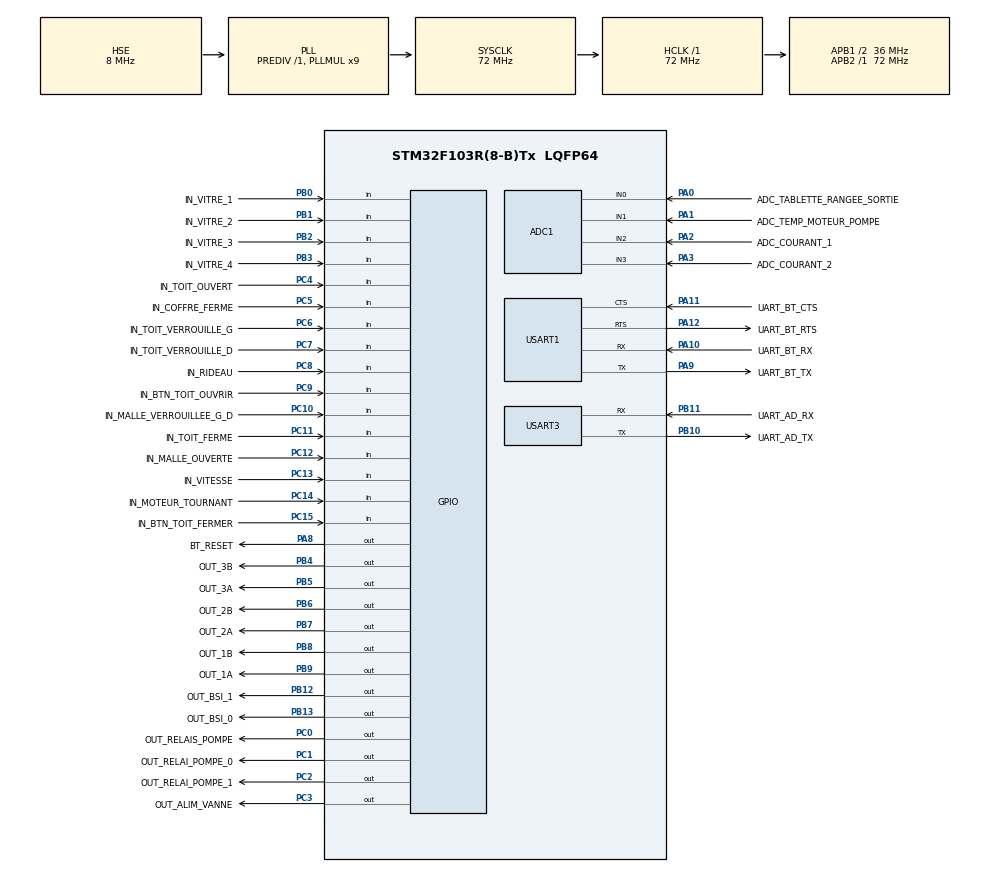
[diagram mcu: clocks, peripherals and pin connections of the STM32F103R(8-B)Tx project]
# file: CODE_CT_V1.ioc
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ADC1.Channel-3\#ChannelRegularConversion=ADC_CHANNEL_0
ADC1.Channel-4\#ChannelRegularConversion=ADC_CHANNEL_1
ADC1.Channel-5\#ChannelRegularConversion=ADC_CHANNEL_2
ADC1.Channel-6\#ChannelRegularConversion=ADC_CHANNEL_3
ADC1.Channel-7\#ChannelRegularConversion=ADC_CHANNEL_TEMPSENSOR
ADC1.ContinuousConvMode=ENABLE
ADC1.NbrOfConversion=5
ADC1.NbrOfConversionFlag=1
ADC1.Rank-3\#ChannelRegularConversion=1
ADC1.Rank-4\#ChannelRegularConversion=2
ADC1.Rank-5\#ChannelRegularConversion=3
ADC1.Rank-6\#ChannelRegularConversion=4
ADC1.Rank-7\#ChannelRegularConversion=5
ADC1.SamplingTime-3\#ChannelRegularConversion=ADC_SAMPLETIME_239CYCLES_5
ADC1.SamplingTime-4\#ChannelRegularConversion=ADC_SAMPLETIME_239CYCLES_5
ADC1.SamplingTime-5\#ChannelRegularConversion=ADC_SAMPLETIME_239CYCLES_5
ADC1.SamplingTime-6\#ChannelRegularConversion=ADC_SAMPLETIME_239CYCLES_5
ADC1.SamplingTime-7\#ChannelRegularConversion=ADC_SAMPLETIME_239CYCLES_5
ADC1.master=1
Dma.ADC1.0.Direction=DMA_PERIPH_TO_MEMORY
Dma.ADC1.0.Instance=DMA1_Channel1
Dma.ADC1.0.MemDataAlignment=DMA_MDATAALIGN_HALFWORD
Dma.ADC1.0.MemInc=DMA_MINC_ENABLE
Dma.ADC1.0.Mode=DMA_CIRCULAR
Dma.ADC1.0.PeriphDataAlignment=DMA_PDATAALIGN_HALFWORD
Dma.ADC1.0.PeriphInc=DMA_PINC_DISABLE
Dma.ADC1.0.Priority=DMA_PRIORITY_LOW
Dma.Request0=ADC1
FREERTOS.Tasks01=TaskToit,40,256,StartTaskToit,Default,NULL,Dynamic,NULL,NULL;TaskBle,24,512,StartTaskBle,Default,NULL,Dynamic,NULL,NULL;TaskDiag,8,128,StartTaskDiag,Default,NULL,Dynamic,NULL,NULL
FREERTOS.configCHECK_FOR_STACK_OVERFLOW=2
FREERTOS.configTOTAL_HEAP_SIZE=10240
Mcu.Family=STM32F1
Mcu.Name=STM32F103R(8-B)Tx
Mcu.Package=LQFP64
NVIC.DMA1_Channel1_IRQn=true\:5\:0\:false\:false\:true\:true\:false\:true\:true
NVIC.PriorityGroup=NVIC_PRIORITYGROUP_4
NVIC.TIM4_IRQn=true\:15\:0\:false\:false\:true\:false\:false\:true\:true
NVIC.TimeBase=TIM4_IRQn
NVIC.TimeBaseIP=TIM4
NVIC.USART1_IRQn=true\:5\:0\:false\:false\:true\:true\:true\:true\:true
PA0-WKUP.GPIO_Label=ADC_TABLETTE_RANGEE_SORTIE
PA0-WKUP.Signal=ADCx_IN0
PA1.GPIO_Label=ADC_TEMP_MOTEUR_POMPE
PA1.Signal=ADCx_IN1
PA10.GPIO_Label=UART_BT_RX
PA10.Mode=Asynchronous
PA10.Signal=USART1_RX
PA11.GPIO_Label=UART_BT_CTS
PA11.Mode=CTS_RTS
PA11.Signal=USART1_CTS
PA12.GPIO_Label=UART_BT_RTS
PA12.Mode=CTS_RTS
PA12.Signal=USART1_RTS
PA13.Mode=Serial_Wire
PA13.Signal=SYS_JTMS-SWDIO
PA14.Mode=Serial_Wire
PA14.Signal=SYS_JTCK-SWCLK
PA2.GPIO_Label=ADC_COURANT_1
PA2.Signal=ADCx_IN2
PA3.GPIO_Label=ADC_COURANT_2
PA3.Signal=ADCx_IN3
PA8.GPIO_Label=BT_RESET
PA8.Signal=GPIO_Output
PA9.GPIO_Label=UART_BT_TX
PA9.Mode=Asynchronous
PA9.Signal=USART1_TX
PB0.GPIO_Label=IN_VITRE_1
PB0.Signal=GPIO_Input
PB1.GPIO_Label=IN_VITRE_2
PB1.Signal=GPIO_Input
PB10.GPIO_Label=UART_AD_TX
PB10.Mode=Asynchronous
PB10.Signal=USART3_TX
PB11.GPIO_Label=UART_AD_RX
PB11.Mode=Asynchronous
PB11.Signal=USART3_RX
PB12.GPIO_Label=OUT_BSI_1
PB12.Signal=GPIO_Output
PB13.GPIO_Label=OUT_BSI_0
PB13.Signal=GPIO_Output
PB2.GPIO_Label=IN_VITRE_3
PB2.Signal=GPIO_Input
PB3.GPIO_Label=IN_VITRE_4
PB3.Signal=GPIO_Input
PB4.GPIO_Label=OUT_3B
PB4.Signal=GPIO_Output
PB5.GPIO_Label=OUT_3A
PB5.Signal=GPIO_Output
PB6.GPIO_Label=OUT_2B
PB6.Signal=GPIO_Output
PB7.GPIO_Label=OUT_2A
PB7.Signal=GPIO_Output
PB8.GPIO_Label=OUT_1B
PB8.Signal=GPIO_Output
PB9.GPIO_Label=OUT_1A
PB9.Signal=GPIO_Output
PC0.GPIO_Label=OUT_RELAIS_POMPE
PC0.Signal=GPIO_Output
PC1.GPIO_Label=OUT_RELAI_POMPE_0
PC1.Signal=GPIO_Output
PC10.GPIO_Label=IN_MALLE_VERROUILLEE_G_D
PC10.Signal=GPIO_Input
PC11.GPIO_Label=IN_TOIT_FERME
PC11.Signal=GPIO_Input
PC12.GPIO_Label=IN_MALLE_OUVERTE
PC12.Signal=GPIO_Input
PC13-TAMPER-RTC.GPIO_Label=IN_VITESSE
PC13-TAMPER-RTC.Signal=GPIO_Input
PC14-OSC32_IN.GPIO_Label=IN_MOTEUR_TOURNANT
PC14-OSC32_IN.Signal=GPIO_Input
PC15-OSC32_OUT.GPIO_Label=IN_BTN_TOIT_FERMER
PC15-OSC32_OUT.Signal=GPIO_Input
PC2.GPIO_Label=OUT_RELAI_POMPE_1
PC2.Signal=GPIO_Output
PC3.GPIO_Label=OUT_ALIM_VANNE
PC3.Signal=GPIO_Output
PC4.GPIO_Label=IN_TOIT_OUVERT
PC4.Signal=GPIO_Input
PC5.GPIO_Label=IN_COFFRE_FERME
PC5.Signal=GPIO_Input
PC6.GPIO_Label=IN_TOIT_VERROUILLE_G
PC6.Signal=GPIO_Input
PC7.GPIO_Label=IN_TOIT_VERROUILLE_D
PC7.Signal=GPIO_Input
PC8.GPIO_Label=IN_RIDEAU
PC8.Signal=GPIO_Input
PC9.GPIO_Label=IN_BTN_TOIT_OUVRIR
PC9.Signal=GPIO_Input
PD0-OSC_IN.Mode=HSE-External-Oscillator
PD0-OSC_IN.Signal=RCC_OSC_IN
PD1-OSC_OUT.Mode=HSE-External-Oscillator
PD1-OSC_OUT.Signal=RCC_OSC_OUT
ProjectManager.HeapSize=0x200
ProjectManager.StackSize=0x400
ProjectManager.TargetToolchain=CMake
RCC.ADCPresc=RCC_ADCPCLK2_DIV6
RCC.AHBFreq_Value=72000000
RCC.APB1CLKDivider=RCC_HCLK_DIV2
RCC.APB1Freq_Value=36000000
RCC.APB1TimFreq_Value=72000000
RCC.APB2Freq_Value=72000000
RCC.APB2TimFreq_Value=72000000
RCC.HCLKFreq_Value=72000000
RCC.PLLMUL=RCC_PLL_MUL9
RCC.PLLSourceVirtual=RCC_PLLSOURCE_HSE
RCC.SYSCLKFreq_VALUE=72000000
RCC.SYSCLKSource=RCC_SYSCLKSOURCE_PLLCLK
RCC.USBFreq_Value=72000000
SH.ADCx_IN0.0=ADC1_IN0,IN0
SH.ADCx_IN1.0=ADC1_IN1,IN1
SH.ADCx_IN2.0=ADC1_IN2,IN2
SH.ADCx_IN3.0=ADC1_IN3,IN3
USART1.VirtualMode=VM_ASYNC
USART3.VirtualMode=VM_ASYNC
VP_ADC1_TempSens_Input.Mode=IN-TempSens
VP_FREERTOS_VS_CMSIS_V2.Mode=CMSIS_V2
VP_SYS_VS_tim4.Mode=TIM4
board=custom

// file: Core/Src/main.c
/* USER CODE BEGIN Header */
/**
  ******************************************************************************
  * @file           : main.c
  * @brief          : Main program body
  ******************************************************************************
  * @attention
  *
  * Copyright (c) 2026 STMicroelectronics.
  * All rights reserved.
  *
  * This software is licensed under terms that can be found in the LICENSE file
  * in the root directory of this software component.
  * If no LICENSE file comes with this software, it is provided AS-IS.
  *
  ******************************************************************************
  */
/* USER CODE END Header */
#include "main.h"
#include "cmsis_os.h"

/* USER CODE BEGIN Includes */
#include "vitres.h"
/* USER CODE END Includes */

ADC_HandleTypeDef hadc1;
DMA_HandleTypeDef hdma_adc1;

UART_HandleTypeDef huart1;
UART_HandleTypeDef huart3;

/* Definitions for TaskToit */
osThreadId_t TaskToitHandle;
const osThreadAttr_t TaskToit_attributes = {
  .name = "TaskToit",
  .stack_size = 256 * 4,
  .priority = (osPriority_t) osPriorityHigh,
};
/* Definitions for TaskBle */
osThreadId_t TaskBleHandle;
const osThreadAttr_t TaskBle_attributes = {
  .name = "TaskBle",
  .stack_size = 512 * 4,
  .priority = (osPriority_t) osPriorityNormal,
};
/* Definitions for TaskDiag */
osThreadId_t TaskDiagHandle;
const osThreadAttr_t TaskDiag_attributes = {
  .name = "TaskDiag",
  .stack_size = 128 * 4,
  .priority = (osPriority_t) osPriorityLow,
};

void SystemClock_Config(void);
static void MX_GPIO_Init(void);
static void MX_DMA_Init(void);
static void MX_USART1_UART_Init(void);
static void MX_USART3_UART_Init(void);
static void MX_ADC1_Init(void);
void StartTaskToit(void *argument);
void StartTaskBle(void *argument);
void StartTaskDiag(void *argument);

int main(void)
{

  /* MCU Configuration--------------------------------------------------------*/

  /* Reset of all peripherals, Initializes the Flash interface and the Systick. */
  HAL_Init();

  /* Configure the system clock */
  SystemClock_Config();

  /* Initialize all configured peripherals */
  MX_GPIO_Init();
  MX_DMA_Init();
  MX_USART1_UART_Init();
  MX_USART3_UART_Init();
  MX_ADC1_Init();

  /* Init scheduler */
  osKernelInitialize();

  /* Create the thread(s) */
  /* creation of TaskToit */
  TaskToitHandle = osThreadNew(StartTaskToit, NULL, &TaskToit_attributes);

  /* creation of TaskBle */
  TaskBleHandle = osThreadNew(StartTaskBle, NULL, &TaskBle_attributes);

  /* creation of TaskDiag */
  TaskDiagHandle = osThreadNew(StartTaskDiag, NULL, &TaskDiag_attributes);

  /* Start scheduler */
  osKernelStart();

  /* We should never get here as control is now taken by the scheduler */

  /* Infinite loop */
  while (1)
  {

  }
}

void SystemClock_Config(void)
{
  RCC_OscInitTypeDef RCC_OscInitStruct = {0};
  RCC_ClkInitTypeDef RCC_ClkInitStruct = {0};
  RCC_PeriphCLKInitTypeDef PeriphClkInit = {0};

  /** Initializes the RCC Oscillators according to the specified parameters
  * in the RCC_OscInitTypeDef structure.
  */
  RCC_OscInitStruct.OscillatorType = RCC_OSCILLATORTYPE_HSE;
  RCC_OscInitStruct.HSEState = RCC_HSE_ON;
  RCC_OscInitStruct.HSEPredivValue = RCC_HSE_PREDIV_DIV1;
  RCC_OscInitStruct.HSIState = RCC_HSI_ON;
  RCC_OscInitStruct.PLL.PLLState = RCC_PLL_ON;
  RCC_OscInitStruct.PLL.PLLSource = RCC_PLLSOURCE_HSE;
  RCC_OscInitStruct.PLL.PLLMUL = RCC_PLL_MUL9;
  if (HAL_RCC_OscConfig(&RCC_OscInitStruct) != HAL_OK)
  {
    Error_Handler();
  }

  /** Initializes the CPU, AHB and APB buses clocks
  */
  RCC_ClkInitStruct.ClockType = RCC_CLOCKTYPE_HCLK|RCC_CLOCKTYPE_SYSCLK
                              |RCC_CLOCKTYPE_PCLK1|RCC_CLOCKTYPE_PCLK2;
  RCC_ClkInitStruct.SYSCLKSource = RCC_SYSCLKSOURCE_PLLCLK;
  RCC_ClkInitStruct.AHBCLKDivider = RCC_SYSCLK_DIV1;
  RCC_ClkInitStruct.APB1CLKDivider = RCC_HCLK_DIV2;
  RCC_ClkInitStruct.APB2CLKDivider = RCC_HCLK_DIV1;

  if (HAL_RCC_ClockConfig(&RCC_ClkInitStruct, FLASH_LATENCY_2) != HAL_OK)
  {
    Error_Handler();
  }
  PeriphClkInit.PeriphClockSelection = RCC_PERIPHCLK_ADC;
  PeriphClkInit.AdcClockSelection = RCC_ADCPCLK2_DIV6;
  if (HAL_RCCEx_PeriphCLKConfig(&PeriphClkInit) != HAL_OK)
  {
    Error_Handler();
  }
}

static void MX_ADC1_Init(void)
{

  ADC_ChannelConfTypeDef sConfig = {0};

  /** Common config
  */
  hadc1.Instance = ADC1;
  hadc1.Init.ScanConvMode = ADC_SCAN_ENABLE;
  hadc1.Init.ContinuousConvMode = ENABLE;
  hadc1.Init.DiscontinuousConvMode = DISABLE;
  hadc1.Init.ExternalTrigConv = ADC_SOFTWARE_START;
  hadc1.Init.DataAlign = ADC_DATAALIGN_RIGHT;
  hadc1.Init.NbrOfConversion = 5;
  if (HAL_ADC_Init(&hadc1) != HAL_OK)
  {
    Error_Handler();
  }

  /** Configure Regular Channel
  */
  sConfig.Channel = ADC_CHANNEL_0;
  sConfig.Rank = ADC_REGULAR_RANK_1;
  sConfig.SamplingTime = ADC_SAMPLETIME_239CYCLES_5;
  if (HAL_ADC_ConfigChannel(&hadc1, &sConfig) != HAL_OK)
  {
    Error_Handler();
  }

  /** Configure Regular Channel
  */
  sConfig.Channel = ADC_CHANNEL_1;
  sConfig.Rank = ADC_REGULAR_RANK_2;
  if (HAL_ADC_ConfigChannel(&hadc1, &sConfig) != HAL_OK)
  {
    Error_Handler();
  }

  /** Configure Regular Channel
  */
  sConfig.Channel = ADC_CHANNEL_2;
  sConfig.Rank = ADC_REGULAR_RANK_3;
  if (HAL_ADC_ConfigChannel(&hadc1, &sConfig) != HAL_OK)
  {
    Error_Handler();
  }

  /** Configure Regular Channel
  */
  sConfig.Channel = ADC_CHANNEL_3;
  sConfig.Rank = ADC_REGULAR_RANK_4;
  if (HAL_ADC_ConfigChannel(&hadc1, &sConfig) != HAL_OK)
  {
    Error_Handler();
  }

  /** Configure Regular Channel
  */
  sConfig.Channel = ADC_CHANNEL_TEMPSENSOR;
  sConfig.Rank = ADC_REGULAR_RANK_5;
  if (HAL_ADC_ConfigChannel(&hadc1, &sConfig) != HAL_OK)
  {
    Error_Handler();
  }

}

static void MX_USART1_UART_Init(void)
{

  huart1.Instance = USART1;
  huart1.Init.BaudRate = 115200;
  huart1.Init.WordLength = UART_WORDLENGTH_8B;
  huart1.Init.StopBits = UART_STOPBITS_1;
  huart1.Init.Parity = UART_PARITY_NONE;
  huart1.Init.Mode = UART_MODE_TX_RX;
  huart1.Init.HwFlowCtl = UART_HWCONTROL_RTS_CTS;
  huart1.Init.OverSampling = UART_OVERSAMPLING_16;
  if (HAL_UART_Init(&huart1) != HAL_OK)
  {
    Error_Handler();
  }

}

static void MX_USART3_UART_Init(void)
{

  huart3.Instance = USART3;
  huart3.Init.BaudRate = 115200;
  huart3.Init.WordLength = UART_WORDLENGTH_8B;
  huart3.Init.StopBits = UART_STOPBITS_1;
  huart3.Init.Parity = UART_PARITY_NONE;
  huart3.Init.Mode = UART_MODE_TX_RX;
  huart3.Init.HwFlowCtl = UART_HWCONTROL_NONE;
  huart3.Init.OverSampling = UART_OVERSAMPLING_16;
  if (HAL_UART_Init(&huart3) != HAL_OK)
  {
    Error_Handler();
  }

}

static void MX_DMA_Init(void)
{

  /* DMA controller clock enable */
  __HAL_RCC_DMA1_CLK_ENABLE();

  /* DMA interrupt init */
  /* DMA1_Channel1_IRQn interrupt configuration */
  HAL_NVIC_SetPriority(DMA1_Channel1_IRQn, 5, 0);
  HAL_NVIC_EnableIRQ(DMA1_Channel1_IRQn);

}

static void MX_GPIO_Init(void)
{
  GPIO_InitTypeDef GPIO_InitStruct = {0};

  /* GPIO Ports Clock Enable */
  __HAL_RCC_GPIOC_CLK_ENABLE();
  __HAL_RCC_GPIOD_CLK_ENABLE();
  __HAL_RCC_GPIOA_CLK_ENABLE();
  __HAL_RCC_GPIOB_CLK_ENABLE();

  /*Configure GPIO pin Output Level */
  HAL_GPIO_WritePin(GPIOC, OUT_RELAIS_POMPE_Pin|OUT_RELAI_POMPE_0_Pin|OUT_RELAI_POMPE_1_Pin|OUT_ALIM_VANNE_Pin, GPIO_PIN_RESET);

  /*Configure GPIO pin Output Level */
  HAL_GPIO_WritePin(GPIOB, OUT_BSI_1_Pin|OUT_BSI_0_Pin|OUT_3B_Pin|OUT_3A_Pin
                          |OUT_2B_Pin|OUT_2A_Pin|OUT_1B_Pin|OUT_1A_Pin, GPIO_PIN_RESET);

  /*Configure GPIO pin Output Level */
  HAL_GPIO_WritePin(BT_RESET_GPIO_Port, BT_RESET_Pin, GPIO_PIN_RESET);

  /*Configure GPIO pins : IN_VITESSE_Pin IN_MOTEUR_TOURNANT_Pin IN_BTN_TOIT_FERMER_Pin IN_TOIT_OUVERT_Pin
                           IN_COFFRE_FERME_Pin IN_TOIT_VERROUILLE_G_Pin IN_TOIT_VERROUILLE_D_Pin IN_RIDEAU_Pin
                           IN_BTN_TOIT_OUVRIR_Pin IN_MALLE_VERROUILLEE_G_D_Pin IN_TOIT_FERME_Pin IN_MALLE_OUVERTE_Pin */
  GPIO_InitStruct.Pin = IN_VITESSE_Pin|IN_MOTEUR_TOURNANT_Pin|IN_BTN_TOIT_FERMER_Pin|IN_TOIT_OUVERT_Pin
                          |IN_COFFRE_FERME_Pin|IN_TOIT_VERROUILLE_G_Pin|IN_TOIT_VERROUILLE_D_Pin|IN_RIDEAU_Pin
                          |IN_BTN_TOIT_OUVRIR_Pin|IN_MALLE_VERROUILLEE_G_D_Pin|IN_TOIT_FERME_Pin|IN_MALLE_OUVERTE_Pin;
  GPIO_InitStruct.Mode = GPIO_MODE_INPUT;
  GPIO_InitStruct.Pull = GPIO_NOPULL;
  HAL_GPIO_Init(GPIOC, &GPIO_InitStruct);

  /*Configure GPIO pins : OUT_RELAIS_POMPE_Pin OUT_RELAI_POMPE_0_Pin OUT_RELAI_POMPE_1_Pin OUT_ALIM_VANNE_Pin */
  GPIO_InitStruct.Pin = OUT_RELAIS_POMPE_Pin|OUT_RELAI_POMPE_0_Pin|OUT_RELAI_POMPE_1_Pin|OUT_ALIM_VANNE_Pin;
  GPIO_InitStruct.Mode = GPIO_MODE_OUTPUT_PP;
  GPIO_InitStruct.Pull = GPIO_NOPULL;
  GPIO_InitStruct.Speed = GPIO_SPEED_FREQ_LOW;
  HAL_GPIO_Init(GPIOC, &GPIO_InitStruct);

  /*Configure GPIO pins : IN_VITRE_1_Pin IN_VITRE_2_Pin IN_VITRE_3_Pin IN_VITRE_4_Pin */
  GPIO_InitStruct.Pin = IN_VITRE_1_Pin|IN_VITRE_2_Pin|IN_VITRE_3_Pin|IN_VITRE_4_Pin;
  GPIO_InitStruct.Mode = GPIO_MODE_INPUT;
  GPIO_InitStruct.Pull = GPIO_NOPULL;
  HAL_GPIO_Init(GPIOB, &GPIO_InitStruct);

  /*Configure GPIO pins : OUT_BSI_1_Pin OUT_BSI_0_Pin OUT_3B_Pin OUT_3A_Pin
                           OUT_2B_Pin OUT_2A_Pin OUT_1B_Pin OUT_1A_Pin */
  GPIO_InitStruct.Pin = OUT_BSI_1_Pin|OUT_BSI_0_Pin|OUT_3B_Pin|OUT_3A_Pin
                          |OUT_2B_Pin|OUT_2A_Pin|OUT_1B_Pin|OUT_1A_Pin;
  GPIO_InitStruct.Mode = GPIO_MODE_OUTPUT_PP;
  GPIO_InitStruct.Pull = GPIO_NOPULL;
  GPIO_InitStruct.Speed = GPIO_SPEED_FREQ_LOW;
  HAL_GPIO_Init(GPIOB, &GPIO_InitStruct);

  /*Configure GPIO pin : BT_RESET_Pin */
  GPIO_InitStruct.Pin = BT_RESET_Pin;
  GPIO_InitStruct.Mode = GPIO_MODE_OUTPUT_PP;
  GPIO_InitStruct.Pull = GPIO_NOPULL;
  GPIO_InitStruct.Speed = GPIO_SPEED_FREQ_LOW;
  HAL_GPIO_Init(BT_RESET_GPIO_Port, &GPIO_InitStruct);

}

void StartTaskToit(void *argument)
{
  /* USER CODE BEGIN 5 */
  /* Infinite loop */
  for(;;)
  {
    Vitres_Process();
    osDelay(20);
  }
  /* USER CODE END 5 */
}

void StartTaskBle(void *argument)
{
  for(;;)
  {
    osDelay(1);
  }
}

void StartTaskDiag(void *argument)
{
  for(;;)
  {
    osDelay(1);
  }
}

void HAL_TIM_PeriodElapsedCallback(TIM_HandleTypeDef *htim)
{
  if (htim->Instance == TIM4)
  {
    HAL_IncTick();
  }
}

void Error_Handler(void)
{
  __disable_irq();
  while (1)
  {
  }
}
